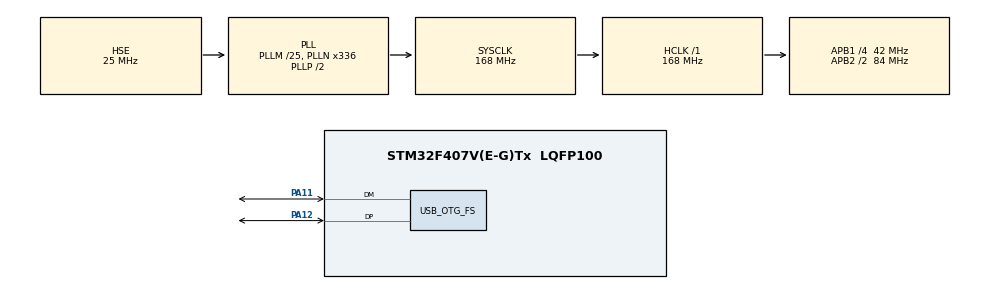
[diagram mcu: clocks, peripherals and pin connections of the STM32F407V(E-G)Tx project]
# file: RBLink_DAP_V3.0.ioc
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Mcu.Family=STM32F4
Mcu.Name=STM32F407V(E-G)Tx
Mcu.Package=LQFP100
NVIC.PriorityGroup=NVIC_PRIORITYGROUP_4
PA11.Mode=Device_Only
PA11.Signal=USB_OTG_FS_DM
PA12.Mode=Device_Only
PA12.Signal=USB_OTG_FS_DP
PH0-OSC_IN.Mode=HSE-External-Oscillator
PH0-OSC_IN.Signal=RCC_OSC_IN
PH1-OSC_OUT.Mode=HSE-External-Oscillator
PH1-OSC_OUT.Signal=RCC_OSC_OUT
ProjectManager.HeapSize=0x800
ProjectManager.StackSize=0x400
ProjectManager.TargetToolchain=MDK-ARM V5.32
RCC.48MHZClocksFreq_Value=48000000
RCC.AHBFreq_Value=168000000
RCC.APB1CLKDivider=RCC_HCLK_DIV4
RCC.APB1Freq_Value=42000000
RCC.APB1TimFreq_Value=84000000
RCC.APB2CLKDivider=RCC_HCLK_DIV2
RCC.APB2Freq_Value=84000000
RCC.APB2TimFreq_Value=168000000
RCC.CortexFreq_Value=168000000
RCC.HCLKFreq_Value=168000000
RCC.HSE_VALUE=25000000
RCC.HSI_VALUE=16000000
RCC.LSE_VALUE=32768
RCC.PLLM=25
RCC.PLLN=336
RCC.PLLQ=7
RCC.SYSCLKFreq_VALUE=168000000
RCC.SYSCLKSource=RCC_SYSCLKSOURCE_PLLCLK
RCC.VCOOutputFreq_Value=336000000
USB_OTG_FS.VirtualMode=Device_Only
board=custom

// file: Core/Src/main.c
/* USER CODE BEGIN Header */
/**
  ******************************************************************************
  * @file           : main.c
  * @brief          : Main program body
  ******************************************************************************
  * @attention
  *
  * Copyright (c) 2026 STMicroelectronics.
  * All rights reserved.
  *
  * This software is licensed under terms that can be found in the LICENSE file
  * in the root directory of this software component.
  * If no LICENSE file comes with this software, it is provided AS-IS.
  *
  ******************************************************************************
  */
/* USER CODE END Header */
#include "main.h"
#include "usb_otg.h"
#include "gpio.h"

/* USER CODE BEGIN Includes */
#include "rblink_board.h"
#include "rblink_debug.h"
#include "rblink_usb.h"
#include "rblink_uart.h"
#include "rblink_wireless.h"
#include "rblink_nor.h"
#include "rblink_bus.h"

/* USER CODE END Includes */

void SystemClock_Config(void);

int main(void)
{

  /* MCU Configuration--------------------------------------------------------*/

  /* Reset of all peripherals, Initializes the Flash interface and the Systick. */
  HAL_Init();

  /* Configure the system clock */
  SystemClock_Config();

  /* Initialize all configured peripherals */
  MX_GPIO_Init();
  /* USER CODE BEGIN 2 */
  RB_Board_Init();
  RB_Debug_Init();
  RB_USB_Init();
  /* Restore target power only after the board safe state and DAP setup. */
  RB_Power_Init();
  RB_Wireless_Init();
  RB_NOR_Init();

  /* DAP initialization performs its board setup again and restores the LEDs
     to their safe inactive state.  Assert the active-high status LED only
     after every subsystem has finished initialization. */
  RB_LED_State(1U);

  /* USER CODE END 2 */

  /* Infinite loop */
  while (1)
  {

    /* USER CODE BEGIN 3 */
    RB_USB_Task();
    RB_Debug_Task();
    RB_UART_Task();
    RB_Wireless_Task();
    RB_Bus_Task();
  }
  /* USER CODE END 3 */
}

void SystemClock_Config(void)
{
  RCC_OscInitTypeDef RCC_OscInitStruct = {0};
  RCC_ClkInitTypeDef RCC_ClkInitStruct = {0};

  /** Configure the main internal regulator output voltage
  */
  __HAL_RCC_PWR_CLK_ENABLE();
  __HAL_PWR_VOLTAGESCALING_CONFIG(PWR_REGULATOR_VOLTAGE_SCALE1);

  /** Initializes the RCC Oscillators according to the specified parameters
  * in the RCC_OscInitTypeDef structure.
  */
  RCC_OscInitStruct.OscillatorType = RCC_OSCILLATORTYPE_HSE;
  RCC_OscInitStruct.HSEState = RCC_HSE_ON;
  RCC_OscInitStruct.PLL.PLLState = RCC_PLL_ON;
  RCC_OscInitStruct.PLL.PLLSource = RCC_PLLSOURCE_HSE;
  RCC_OscInitStruct.PLL.PLLM = 25;
  RCC_OscInitStruct.PLL.PLLN = 336;
  RCC_OscInitStruct.PLL.PLLP = RCC_PLLP_DIV2;
  RCC_OscInitStruct.PLL.PLLQ = 7;
  if (HAL_RCC_OscConfig(&RCC_OscInitStruct) != HAL_OK)
  {
    Error_Handler();
  }

  /** Initializes the CPU, AHB and APB buses clocks
  */
  RCC_ClkInitStruct.ClockType = RCC_CLOCKTYPE_HCLK|RCC_CLOCKTYPE_SYSCLK
                              |RCC_CLOCKTYPE_PCLK1|RCC_CLOCKTYPE_PCLK2;
  RCC_ClkInitStruct.SYSCLKSource = RCC_SYSCLKSOURCE_PLLCLK;
  RCC_ClkInitStruct.AHBCLKDivider = RCC_SYSCLK_DIV1;
  RCC_ClkInitStruct.APB1CLKDivider = RCC_HCLK_DIV4;
  RCC_ClkInitStruct.APB2CLKDivider = RCC_HCLK_DIV2;

  if (HAL_RCC_ClockConfig(&RCC_ClkInitStruct, FLASH_LATENCY_5) != HAL_OK)
  {
    Error_Handler();
  }
}

void Error_Handler(void)
{
  __disable_irq();
  while (1)
  {
  }
}
